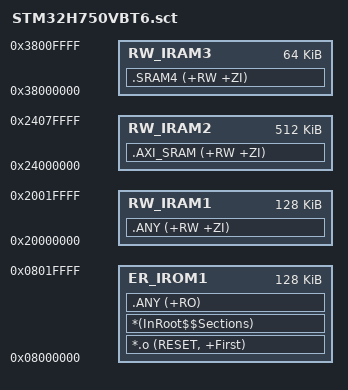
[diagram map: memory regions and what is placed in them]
; *************************************************************
; STM32H750VBT6 Scatter File - Stable Flash Version
; Flash: 128KB (0x08000000 - 0x0801FFFF)
; DTCM:  128KB (0x20000000 - 0x2001FFFF)
; AXI SRAM: 512KB (0x24000000 - 0x2407FFFF)
; *************************************************************

LR_IROM1 0x08000000 0x00020000  {    ; load region size 128KB
  ER_IROM1 0x08000000 0x00020000  {  ; code region
   *.o (RESET, +First)
   *(InRoot$$Sections)
   .ANY (+RO)
  }
  RW_IRAM1 0x20000000 0x00020000  {  ; DTCM 128KB
   .ANY (+RW +ZI)
  }
  RW_IRAM2 0x24000000 0x00080000  {  ; AXI SRAM 512KB
   .AXI_SRAM (+RW +ZI)
  }
  RW_IRAM3 0x38000000 0x00010000  {  ; SRAM4 64KB
   .SRAM4 (+RW +ZI)
  }
}
